# STM32F072xB register map
File version: 1.0
Registers are 32-bit, read-write, reset 0x0 unless marked. A register's access mark holds for its fields unless they carry their own. Offsets are from the block's base; [hi:lo] are bit positions; {n}, {i} and the like mark numbered series.

## USB — Universal Serial Bus Full Speed Device
Base 0x40005C00
{0x0+4i} EP{i}R 16-bit (i=0..7) — USB Endpoint {i} register
0x40 CNTR 16-bit — Control register
0x44 ISTR 16-bit — Interrupt status register
0x48 FNR 16-bit — Frame number register
0x4C DADDR 16-bit — Device address register
0x50 BTABLE 16-bit — Buffer Table address register
0x54 LPMCSR 16-bit — LPM Control and Status register
0x58 BCDR 16-bit — Battery Charging detector register

## CRS — Clock Recovery System
Base 0x40006C00
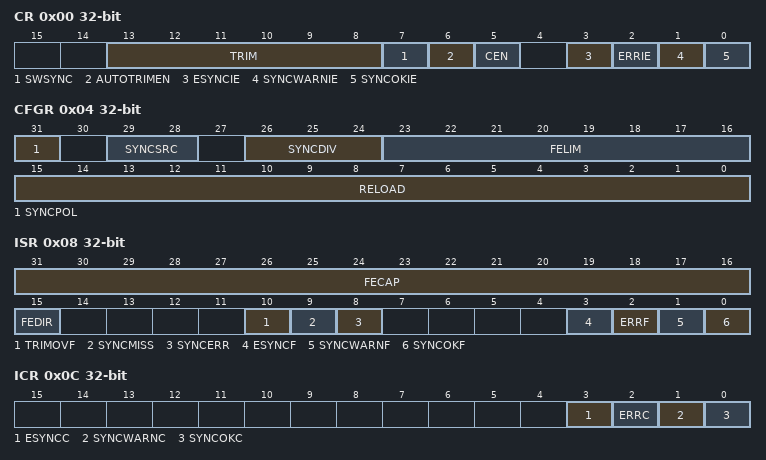
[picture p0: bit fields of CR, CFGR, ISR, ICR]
0x00 CR — CRS ccontrol register
  [13:8] TRIM, [7] SWSYNC, [6] AUTOTRIMEN, [5] CEN, [3] ESYNCIE, [2] ERRIE, [1] SYNCWARNIE, [0] SYNCOKIE
0x04 CFGR — CRS configuration register
  [31] SYNCPOL
    0=RISING (Synchro Active on rising edge (default)); 1=FALLING (Synchro Active on falling edge)
  [29:28] SYNCSRC
    0=GPIO (Synchro Signal source GPIO); 1=LSE (Synchro Signal source LSE); 2=USB (Synchro Signal source USB SOF (default))
  [26:24] SYNCDIV
    0=DIV_1 (Synchro Signal not divided (default)); 1=DIV_2 (Synchro Signal divided by 2); 2=DIV_4 (Synchro Signal divided by 4); 3=DIV_8 (Synchro Signal divided by 8); 4=DIV_16 (Synchro Signal divided by 16); 5=DIV_32 (Synchro Signal divided by 32); 6=DIV_64 (Synchro Signal divided by 64); 7=DIV_128 (Synchro Signal divided by 128)
  [23:16] FELIM
  [15:0] RELOAD
0x08 ISR — CRS interrupt and status register
  [31:16] FECAP
  [15] FEDIR
    0=UP (Upcounting direction, the actual frequency is above the target); 1=DOWN (Downcounting direction, the actual frequency is below the target)
  [10] TRIMOVF
  [9] SYNCMISS
  [8] SYNCERR
  [3] ESYNCF
  [2] ERRF
  [1] SYNCWARNF
  [0] SYNCOKF
0x0C ICR — CRS interrupt flag clear register
  [3] ESYNCC, [2] ERRC, [1] SYNCWARNC, [0] SYNCOKC

## PWR — Power Control
Base 0x40007000
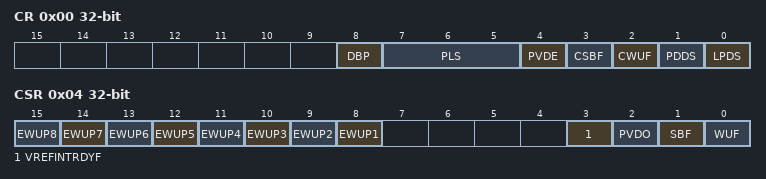
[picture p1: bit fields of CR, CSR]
0x00 CR — PWR power control register
  [8] DBP — Disable Backup Domain write protection
  [7:5] PLS — PLS[2:0] bits (PVD Level Selection)
    {v}=PVDLEVEL_{v} (Voltage threshold {v}) (v=0..7)
  [4] PVDE — Power Voltage Detector Enable
  [3] CSBF — Clear Standby Flag
  [2] CWUF — Clear Wakeup Flag
  [1] PDDS — Power Down Deepsleep
  [0] LPDS — Low-power Deepsleep
    0=MAIN (Voltage Regulator in main mode during deepsleep mode); 1=LOW_POWER (Voltage Regulator in low-power mode during deepsleep mode)
0x04 CSR — PWR power control/status register
  [n+7] EWUP{n} (n=1..8) — Enable WKUP pin {n}
  [3] VREFINTRDYF — Internal voltage reference (VREFINT) ready flag
  [2] PVDO — PVD Output
  [1] SBF — Standby Flag
  [0] WUF — Wakeup Flag

## DAC — Digital to Analog Converter
Base 0x40007400
Same registers: DAC1 0x40007400 (alternate view of DAC)
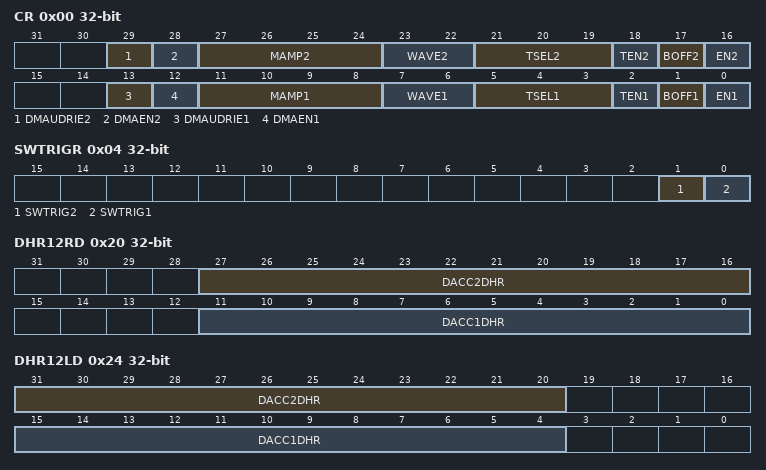
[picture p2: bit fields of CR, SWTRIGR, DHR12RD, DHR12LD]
0x00 CR — DAC control register
  [29] DMAUDRIE2 — DAC channel2 DMA Underrun Interrupt enable
  [28] DMAEN2 — DAC channel2 DMA enabled
  [27:24] MAMP2 — MAMP2[3:0] (DAC channel2 Mask/Amplitude selector)
  [23:22] WAVE2 — WAVE2[1:0] (DAC channel2 noise/triangle wave generation enable)
  [21:19] TSEL2 — TSEL2[2:0] (DAC channel2 Trigger selection)
  [18] TEN2 — DAC channel2 Trigger enable
  [17] BOFF2 — DAC channel2 output buffer disable
  [16] EN2 — DAC channel2 enable
  [13] DMAUDRIE1 — DAC channel1 DMA Underrun Interrupt enable
  [12] DMAEN1 — DAC channel1 DMA enable
  [11:8] MAMP1 — MAMP1[3:0] (DAC channel1 Mask/Amplitude selector)
  [7:6] WAVE1 — WAVE1[1:0] (DAC channel1 noise/triangle wave generation enable)
  [5:3] TSEL1 — TSEL1[2:0] (DAC channel1 Trigger selection)
  [2] TEN1 — DAC channel1 Trigger enable
  [1] BOFF1 — DAC channel1 output buffer disable
  [0] EN1 — DAC channel1 enable
0x04 SWTRIGR — DAC software trigger register
  [1] SWTRIG2 — DAC channel2 software trigger
  [0] SWTRIG1 — DAC channel1 software trigger
0x08 DHR12R1 — DAC channel1 12-bit right-aligned data holding register
  [11:0] DACC1DHR — DAC channel1 12-bit Right aligned data
0x0C DHR12L1 — DAC channel1 12-bit left aligned data holding register
  [15:4] DACC1DHR — DAC channel1 12-bit Left aligned data
0x10 DHR8R1 — DAC channel1 8-bit right aligned data holding register
  [7:0] DACC1DHR — DAC channel1 8-bit Right aligned data
0x14 DHR12R2 — DAC channel2 12-bit right aligned data holding register
  [11:0] DACC2DHR — DAC channel2 12-bit Right aligned data
0x18 DHR12L2 — DAC channel2 12-bit left aligned data holding register
  [15:4] DACC2DHR — DAC channel2 12-bit Left aligned data
0x1C DHR8R2 — DAC channel2 8-bit right-aligned data holding register
  [7:0] DACC2DHR — DAC channel2 8-bit Right aligned data
0x20 DHR12RD — Dual DAC 12-bit right-aligned data holding register
  [27:16] DACC2DHR — DAC channel2 12-bit Right aligned data
  [11:0] DACC1DHR — DAC channel1 12-bit Right aligned data
0x24 DHR12LD — DUAL DAC 12-bit left aligned data holding register
  [31:20] DACC2DHR — DAC channel2 12-bit Left aligned data
  [15:4] DACC1DHR — DAC channel1 12-bit Left aligned data
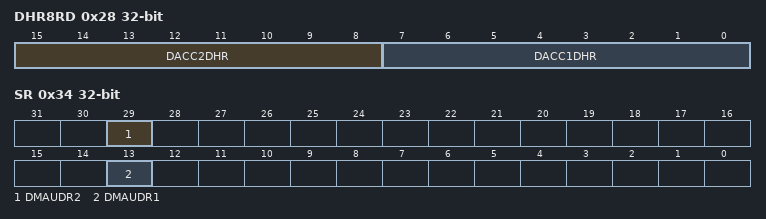
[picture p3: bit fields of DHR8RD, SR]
0x28 DHR8RD — DUAL DAC 8-bit right aligned data holding register
  [15:8] DACC2DHR — DAC channel2 8-bit Right aligned data
  [7:0] DACC1DHR — DAC channel1 8-bit Right aligned data
0x2C DOR1 — DAC channel1 data output register
  [11:0] DACC1DOR — DAC channel1 data output
0x30 DOR2 — DAC channel2 data output register
  [11:0] DACC2DOR — DAC channel2 data output
0x34 SR — DAC status register
  [29] DMAUDR2 — DAC channel2 DMA underrun flag
  [13] DMAUDR1 — DAC channel1 DMA underrun flag
